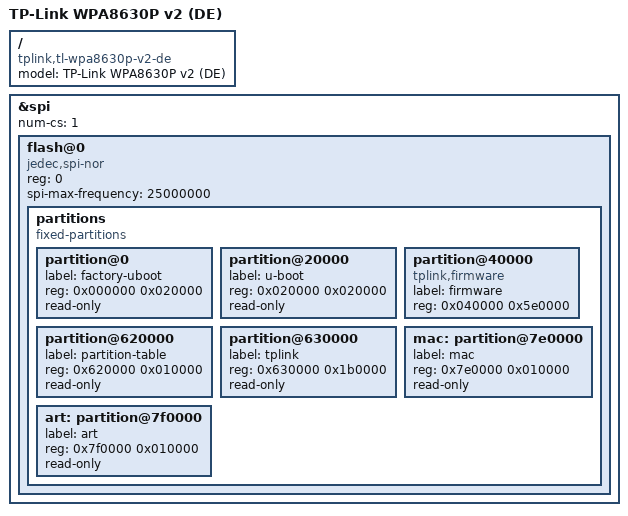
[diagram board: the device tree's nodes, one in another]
// SPDX-License-Identifier: GPL-2.0-or-later OR MIT
/dts-v1/;

#include "qca9563_tplink_tl-wpa8630p-v2.dtsi"

/ {
	compatible = "tplink,tl-wpa8630p-v2-de", "qca,qca9563";
	model = "TP-Link WPA8630P v2 (DE)";
};


&spi {
	status = "okay";

	num-cs = <1>;

	flash@0 {
		compatible = "jedec,spi-nor";
		reg = <0>;
		spi-max-frequency = <25000000>;

		partitions {
			compatible = "fixed-partitions";
			#address-cells = <1>;
			#size-cells = <1>;

			partition@0 {
				label = "factory-uboot";
				reg = <0x000000 0x020000>;
				read-only;
			};

			partition@20000 {
				label = "u-boot";
				reg = <0x020000 0x020000>;
				read-only;
			};

			partition@40000 {
				compatible = "tplink,firmware";
				label = "firmware";
				reg = <0x040000 0x5e0000>;
			};

			partition@620000 {
				label = "partition-table";
				reg = <0x620000 0x010000>;
				read-only;
			};

			partition@630000 {
				label = "tplink";
				reg = <0x630000 0x1b0000>;
				read-only;
			};

			mac: partition@7e0000 {
				label = "mac";
				reg = <0x7e0000 0x010000>;
				read-only;
			};

			art: partition@7f0000 {
				label = "art";
				reg = <0x7f0000 0x010000>;
				read-only;
			};
		};
	};
};
